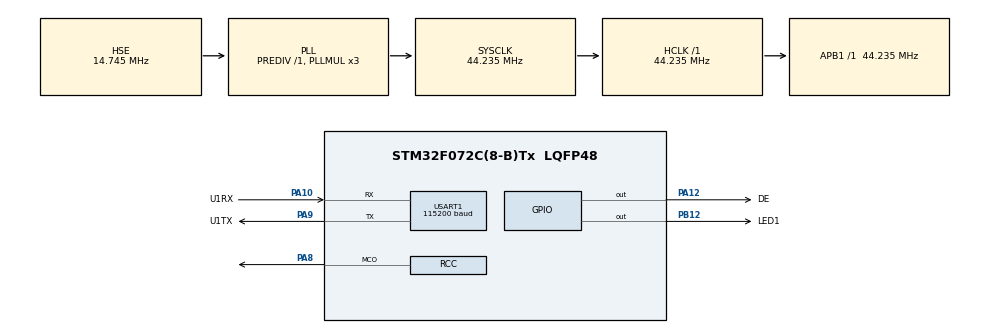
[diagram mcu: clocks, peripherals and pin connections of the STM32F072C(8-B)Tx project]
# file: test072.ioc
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Mcu.Family=STM32F0
Mcu.Name=STM32F072C(8-B)Tx
Mcu.Package=LQFP48
PA10.GPIO_Label=U1RX
PA10.GPIO_PuPd=GPIO_PULLUP
PA10.Mode=Asynchronous
PA10.Signal=USART1_RX
PA12.GPIO_Label=DE
PA12.Signal=GPIO_Output
PA13.Mode=Serial_Wire
PA13.Signal=SYS_SWDIO
PA14.Mode=Serial_Wire
PA14.Signal=SYS_SWCLK
PA8.Mode=Clock-out
PA8.Signal=RCC_MCO
PA9.GPIO_Label=U1TX
PA9.Mode=Asynchronous
PA9.Signal=USART1_TX
PB12.GPIO_Label=LED1
PB12.Signal=GPIO_Output
PB8.GPIO_Speed=GPIO_SPEED_FREQ_LOW
PB8.Signal=CAN_RX
PB9.GPIO_Speed=GPIO_SPEED_FREQ_LOW
PB9.Signal=CAN_TX
PF0-OSC_IN.Mode=HSE-External-Clock-Source
PF0-OSC_IN.Signal=RCC_OSC_IN
ProjectManager.HeapSize=0x200
ProjectManager.StackSize=0x400
ProjectManager.TargetToolchain=STM32CubeIDE
RCC.AHBFreq_Value=44235000
RCC.APB1Freq_Value=44235000
RCC.APB1TimFreq_Value=44235000
RCC.HCLKFreq_Value=44235000
RCC.HSE_VALUE=14745000
RCC.MSICalibrationValue=0
RCC.PLLMUL=RCC_PLL_MUL3
RCC.PLLSourceVirtual=RCC_PLLSOURCE_HSE
RCC.PWR_Regulator_Voltage_Scale=PWR_REGULATOR_VOLTAGE_SCALE1
RCC.RCC_MCODiv=RCC_MCODIV_32
RCC.SYSCLKFreq_VALUE=44235000
RCC.SYSCLKSource=RCC_SYSCLKSOURCE_PLLCLK
USART1.AutoBaudRateEnableParam=UART_ADVFEATURE_AUTOBAUDRATE_DISABLE
USART1.BaudRate=115200
USART1.DMADisableonRxErrorParam=ADVFEATURE_DMA_ENABLEONRXERROR
USART1.DataInvertParam=ADVFEATURE_DATAINV_DISABLE
USART1.MSBFirstParam=ADVFEATURE_MSBFIRST_DISABLE
USART1.Mode=MODE_TX_RX
USART1.OneBitSampling=UART_ONE_BIT_SAMPLE_DISABLE
USART1.OverSampling=UART_OVERSAMPLING_16
USART1.OverrunDisableParam=ADVFEATURE_OVERRUN_ENABLE
USART1.Parity=PARITY_NONE
USART1.RxPinLevelInvertParam=ADVFEATURE_RXINV_DISABLE
USART1.StopBits=STOPBITS_1
USART1.SwapParam=ADVFEATURE_SWAP_DISABLE
USART1.TxPinLevelInvertParam=ADVFEATURE_TXINV_DISABLE
USART1.VirtualMode-Asynchronous=VM_ASYNC
USART1.WordLength=WORDLENGTH_8B
VP_CRC_VS_CRC.Mode=CRC_Activate
board=custom

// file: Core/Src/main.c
/* USER CODE BEGIN Header */
/**
  ******************************************************************************
  * @file           : main.c
  * @brief          : Main program body
  ******************************************************************************
  * @attention
  *
  * Copyright (c) 2025 STMicroelectronics.
  * All rights reserved.
  *
  * This software is licensed under terms that can be found in the LICENSE file
  * in the root directory of this software component.
  * If no LICENSE file comes with this software, it is provided AS-IS.
  *
  ******************************************************************************
  */
/* USER CODE END Header */
#include "main.h"
#include "crc.h"
#include "usart.h"
#include "gpio.h"

void SystemClock_Config(void);

int main(void)
{

  /* MCU Configuration--------------------------------------------------------*/

  /* Reset of all peripherals, Initializes the Flash interface and the Systick. */
  HAL_Init();

  /* Configure the system clock */
  SystemClock_Config();

  /* Initialize all configured peripherals */
  MX_GPIO_Init();
  MX_USART1_UART_Init();
  MX_CRC_Init();

  /* Infinite loop */
  /* USER CODE BEGIN WHILE */
  while (1)
  {
	  LED1_GPIO_Port->BSRR= LED1_Pin;
	  HAL_Delay(50);
	  LED1_GPIO_Port->BRR= LED1_Pin;
	  HAL_Delay(50);

    /* USER CODE END WHILE */

  }
}

void SystemClock_Config(void)
{
  RCC_OscInitTypeDef RCC_OscInitStruct = {0};
  RCC_ClkInitTypeDef RCC_ClkInitStruct = {0};
  RCC_PeriphCLKInitTypeDef PeriphClkInit = {0};

  /** Initializes the RCC Oscillators according to the specified parameters
  * in the RCC_OscInitTypeDef structure.
  */
  RCC_OscInitStruct.OscillatorType = RCC_OSCILLATORTYPE_HSE;
  RCC_OscInitStruct.HSEState = RCC_HSE_BYPASS;
  RCC_OscInitStruct.PLL.PLLState = RCC_PLL_ON;
  RCC_OscInitStruct.PLL.PLLSource = RCC_PLLSOURCE_HSE;
  RCC_OscInitStruct.PLL.PLLMUL = RCC_PLL_MUL3;
  RCC_OscInitStruct.PLL.PREDIV = RCC_PREDIV_DIV1;
  if (HAL_RCC_OscConfig(&RCC_OscInitStruct) != HAL_OK)
  {
    Error_Handler();
  }

  /** Initializes the CPU, AHB and APB buses clocks
  */
  RCC_ClkInitStruct.ClockType = RCC_CLOCKTYPE_HCLK|RCC_CLOCKTYPE_SYSCLK
                              |RCC_CLOCKTYPE_PCLK1;
  RCC_ClkInitStruct.SYSCLKSource = RCC_SYSCLKSOURCE_PLLCLK;
  RCC_ClkInitStruct.AHBCLKDivider = RCC_SYSCLK_DIV1;
  RCC_ClkInitStruct.APB1CLKDivider = RCC_HCLK_DIV1;

  if (HAL_RCC_ClockConfig(&RCC_ClkInitStruct, FLASH_LATENCY_1) != HAL_OK)
  {
    Error_Handler();
  }
  PeriphClkInit.PeriphClockSelection = RCC_PERIPHCLK_USART1;
  PeriphClkInit.Usart1ClockSelection = RCC_USART1CLKSOURCE_PCLK1;
  if (HAL_RCCEx_PeriphCLKConfig(&PeriphClkInit) != HAL_OK)
  {
    Error_Handler();
  }
  HAL_RCC_MCOConfig(RCC_MCO, RCC_MCO1SOURCE_SYSCLK, RCC_MCODIV_32);
}

void Error_Handler(void)
{
  __disable_irq();
  while (1)
  {
  }
}
